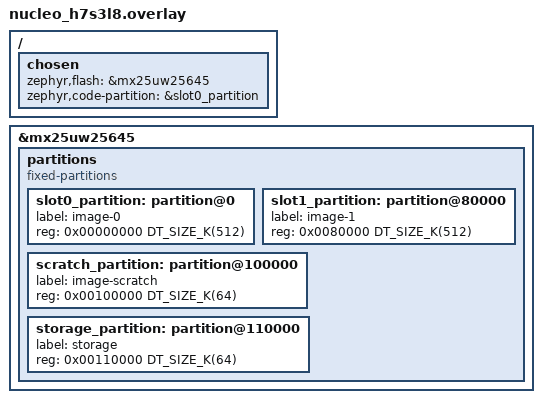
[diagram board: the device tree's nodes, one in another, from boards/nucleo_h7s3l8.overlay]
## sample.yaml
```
sample:
  description: Hello World sample from external flash
    application
  name: hello world xip
tests:
  sample.boards.st.hello_world_xip:
    tags: introduction
    sysbuild: true
    extra_args:
      - SB_CONFIG_BOOTLOADER_MCUBOOT=y
    integration_platforms:
      - stm32h573i_dk
    platform_allow:
      - stm32h573i_dk
```

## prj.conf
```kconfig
#CONFIG_XIP=y
```

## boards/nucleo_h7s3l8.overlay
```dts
/*
 * Copyright (c) 2025 STMicroelectronics
 *
 * SPDX-License-Identifier: Apache-2.0
 */

/*
 * Define the device, controller and partition to be the external memory
 * for running the application in external NOR from MCUboot
 */
/ {
	chosen {
		zephyr,flash = &mx25uw25645;
		zephyr,code-partition = &slot0_partition;
	};
};

&mx25uw25645 {
		partitions {
			compatible = "fixed-partitions";
			#address-cells = <1>;
			#size-cells = <1>;

			slot0_partition: partition@0 {
				label = "image-0";
				reg = <0x00000000 DT_SIZE_K(512)>;
			};
			slot1_partition: partition@80000 {
				label = "image-1";
				reg = <0x0080000 DT_SIZE_K(512)>;
			};
			scratch_partition: partition@100000 {
				label = "image-scratch";
				reg = <0x00100000 DT_SIZE_K(64)>;
			};
			storage_partition: partition@110000 {
				label = "storage";
				reg = <0x00110000 DT_SIZE_K(64)>;
			};
		};
};
```

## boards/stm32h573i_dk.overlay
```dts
/*
 * Copyright (c) 2025 STMicroelectronics
 *
 * SPDX-License-Identifier: Apache-2.0
 */

/*
 * Define the device, controller and partition to be the external memory
 * for running the application in external NOR from MCUboot
 */
/ {
	chosen {
		zephyr,flash = &mx25lm51245;
		zephyr,flash-controller = &mx25lm51245;
	};
};
```

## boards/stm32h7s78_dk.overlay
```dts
/*
 * Copyright (c) 2025 STMicroelectronics
 *
 * SPDX-License-Identifier: Apache-2.0
 */

/*
 * Define the device, controller and partition to be the external memory
 * for running the application in external NOR from MCUboot
 */
/ {
	chosen {
		zephyr,flash = &mx66uw1g45;
		zephyr,code-partition = &slot0_partition;
	};
};

&mx66uw1g45 {
	partitions {
		compatible = "fixed-partitions";
		#address-cells = <1>;
		#size-cells = <1>;

		slot0_partition: partition@0 {
			label = "image-0";
			reg = <0x00000000 DT_SIZE_K(512)>;
		};
		slot1_partition: partition@80000 {
				label = "image-1";
			reg = <0x0080000 DT_SIZE_K(512)>;
		};
		scratch_partition: partition@100000 {
			label = "image-scratch";
			reg = <0x00100000 DT_SIZE_K(64)>;
		};
		storage_partition: partition@110000 {
			label = "storage";
			reg = <0x00110000 DT_SIZE_K(64)>;
		};
	};
};
```

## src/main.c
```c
/*
 * Copyright (c) 2025 STMicroelectronics
 *
 * SPDX-License-Identifier: Apache-2.0
 */

#include <stdio.h>
#include <zephyr/kernel.h>
#include <zephyr/drivers/gpio.h>
#include <zephyr/toolchain/common.h>

/* 1000 msec = 1 sec */
#define SLEEP_TIME_MS   1000

/* The devicetree node identifier for the "led0" alias. */
#define LED0_NODE DT_ALIAS(led0)

/*
 * A build error on this line means your board is unsupported.
 * See the sample documentation for information on how to fix this.
 */
static const struct gpio_dt_spec led0 = GPIO_DT_SPEC_GET(LED0_NODE, gpios);

/* Inline Function to display the PC register --> proove where the application is running */
ALWAYS_INLINE __STATIC_INLINE uint32_t __get_PC(void)
{
	register uint32_t result;

	__ASM volatile ("MOV %0, PC\n" : "=r" (result));
	return result;
}

int main(void)
{
	int ret;

	printf("Hello World! from external flash  %s\n", CONFIG_BOARD);
	printf("--> PC at 0x%x\n", __get_PC());

	if (!gpio_is_ready_dt(&led0)) {
		return -1;
	}

	ret = gpio_pin_configure_dt(&led0, GPIO_OUTPUT_ACTIVE);
	if (ret < 0) {
		return -1;
	}

	while (1) {
		ret = gpio_pin_toggle_dt(&led0);
		if (ret < 0) {
			return -1;
		}

		k_msleep(SLEEP_TIME_MS);
	}
	return 0;
}
```
